# STM32L4P5 register map
File version: 1.8
CPU: CM4 r0p1, little endian, MPU, FPU, 4 interrupt priority bits
Registers are 32-bit, read-write, reset 0x0 unless marked. A register's access mark holds for its fields unless they carry their own. Offsets are from the block's base; [hi:lo] are bit positions; lines under a group give offsets from that group; {n}, {i} and the like mark numbered series.

## VREFBUF — Voltage reference buffer
Base 0x40010030
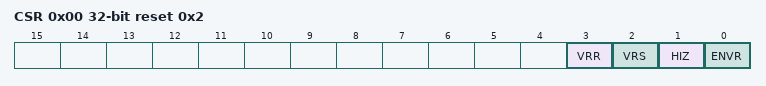
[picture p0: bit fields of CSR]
0x00 CSR access per field reset 0x2 — VREF control and status register
  [3] VRR ro — Voltage reference buffer ready
  [2] VRS rw — Voltage reference scale
  [1] HIZ rw — High impedance mode
  [0] ENVR rw — Voltage reference buffer enable
0x04 CCR — calibration control register
  [5:0] TRIM — Trimming code

## OTG_FS_HOST — USB on the go full speed
Base 0x50000400
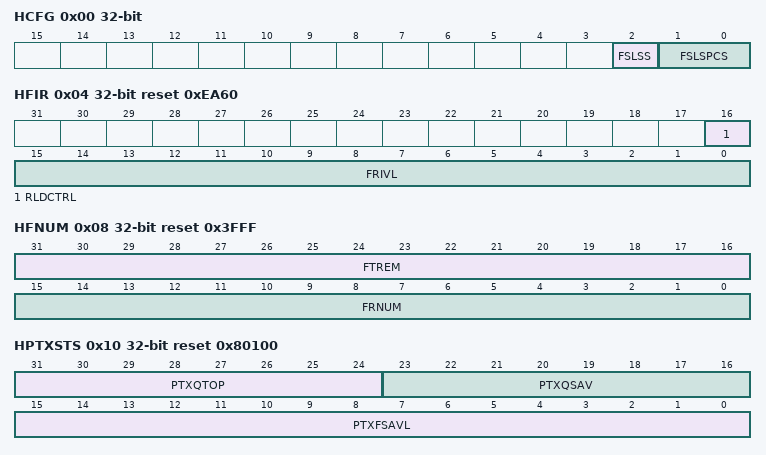
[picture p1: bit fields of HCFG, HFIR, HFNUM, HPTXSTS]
0x00 HCFG — OTG_FS host configuration register (OTG_FS_HCFG)
  [2] FSLSS — FS- and LS-only support
  [1:0] FSLSPCS — FS/LS PHY clock select
0x04 HFIR reset 0xEA60 — OTG_FS Host frame interval register
  [16] RLDCTRL — Reload control
  [15:0] FRIVL — Frame interval
0x08 HFNUM ro reset 0x3FFF — OTG_FS host frame number/frame time remaining register (OTG_FS_HFNUM)
  [31:16] FTREM — Frame time remaining
  [15:0] FRNUM — Frame number
0x10 HPTXSTS access per field reset 0x80100 — OTG_FS_Host periodic transmit FIFO/queue status register (OTG_FS_HPTXSTS)
  [31:24] PTXQTOP ro — Top of the periodic transmit request queue
  [23:16] PTXQSAV ro — Periodic transmit request queue space available
  [15:0] PTXFSAVL rw — Periodic transmit data FIFO space available
0x14 HAINT ro — OTG_FS Host all channels interrupt register
  [15:0] HAINT — Channel interrupts
0x18 HAINTMSK — OTG_FS host all channels interrupt mask register
  [15:0] HAINTM — Channel interrupt mask
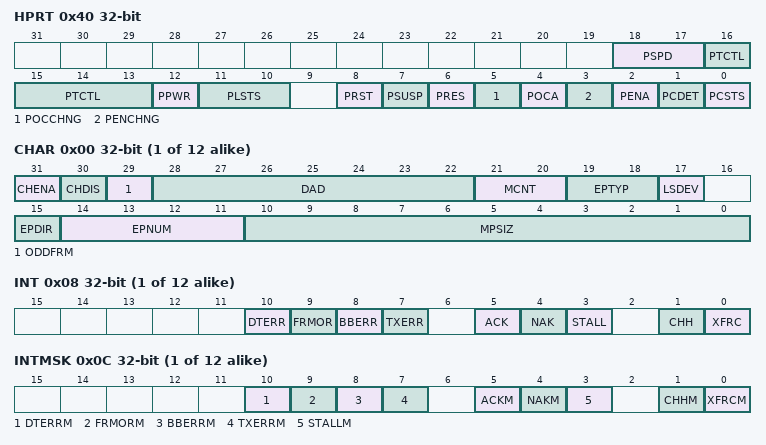
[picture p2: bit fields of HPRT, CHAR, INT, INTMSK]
0x40 HPRT access per field — OTG_FS host port control and status register (OTG_FS_HPRT)
  [18:17] PSPD ro — Port speed
  [16:13] PTCTL rw — Port test control
  [12] PPWR rw — Port power
  [11:10] PLSTS ro — Port line status
  [8] PRST rw — Port reset
  [7] PSUSP rw — Port suspend
  [6] PRES rw — Port resume
  [5] POCCHNG rw — Port overcurrent change
  [4] POCA ro — Port overcurrent active
  [3] PENCHNG rw — Port enable/disable change
  [2] PENA rw — Port enable
  [1] PCDET rw — Port connect detected
  [0] PCSTS ro — Port connect status
{0x100+0x20*i} HC{i} (i=0..11) group — Host channel
  0x00 CHAR — OTG_FS host channel-0 characteristics register (OTG_FS_HCCHAR0)
    [31] CHENA — Channel enable
    [30] CHDIS — Channel disable
    [29] ODDFRM — Odd frame
    [28:22] DAD — Device address
    [21:20] MCNT — Multicount
    [19:18] EPTYP — Endpoint type
    [17] LSDEV — Low-speed device
    [15] EPDIR — Endpoint direction
    [14:11] EPNUM — Endpoint number
    [10:0] MPSIZ — Maximum packet size
  0x08 INT — OTG_FS host channel-0 interrupt register (OTG_FS_HCINT0)
    [10] DTERR — Data toggle error
    [9] FRMOR — Frame overrun
    [8] BBERR — Babble error
    [7] TXERR — Transaction error
    [5] ACK — ACK response received/transmitted interrupt
    [4] NAK — NAK response received interrupt
    [3] STALL — STALL response received interrupt
    [1] CHH — Channel halted
    [0] XFRC — Transfer completed
  0x0C INTMSK — OTG_FS host channel-0 mask register (OTG_FS_HCINTMSK0)
    [10] DTERRM — Data toggle error mask
    [9] FRMORM — Frame overrun mask
    [8] BBERRM — Babble error mask
    [7] TXERRM — Transaction error mask
    [5] ACKM — ACK response received/transmitted interrupt mask
    [4] NAKM — NAK response received interrupt mask
    [3] STALLM — STALL response received interrupt mask
    [1] CHHM — Channel halted mask
    [0] XFRCM — Transfer completed mask
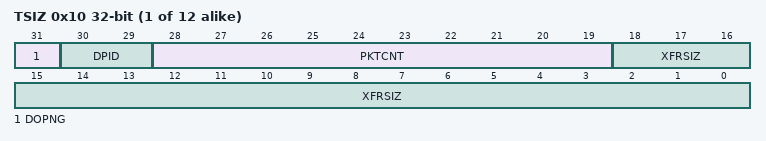
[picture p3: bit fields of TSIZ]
  0x10 TSIZ — OTG_FS host channel-0 transfer size register
    [31] DOPNG — Do Ping
    [30:29] DPID — Data PID
    [28:19] PKTCNT — Packet count
    [18:0] XFRSIZ — Transfer size

## OTG_FS_PWRCLK — USB on the go full speed
Base 0x50000E00
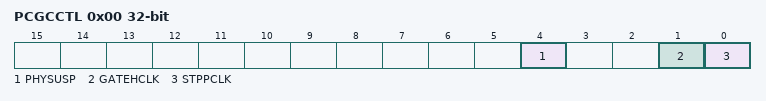
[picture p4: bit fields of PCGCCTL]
0x00 PCGCCTL — OTG_FS power and clock gating control register (OTG_FS_PCGCCTL)
  [4] PHYSUSP — PHY Suspended
  [1] GATEHCLK
  [0] STPPCLK — Stop PHY clock
